# ATSAMA5D225CD1M register map
Vendor: Microchip Technology; Series: SAMA5D2; File version: 0
Registers are 32-bit, read-write, reset 0x0 unless marked. A register's access mark holds for its fields unless they carry their own. Offsets are from the block's base; [hi:lo] are bit positions; {n}, {i} and the like mark numbered series; 'fields as' and 'values as' point back to an identical list.

## PIT — Periodic Interval Timer
Base 0xF8048030; register names take the prefix PIT_
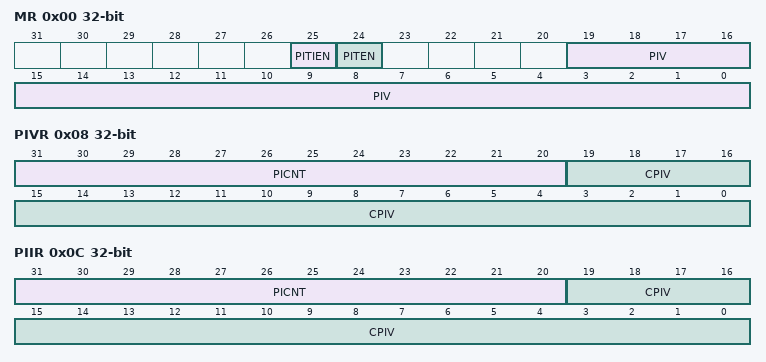
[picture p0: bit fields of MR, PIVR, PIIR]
0x00 MR — Mode Register
  [25] PITIEN — Periodic Interval Timer Interrupt Enable
  [24] PITEN — Period Interval Timer Enabled
  [19:0] PIV — Periodic Interval Value
0x04 SR ro — Status Register
  [0] PITS — Periodic Interval Timer Status
0x08 PIVR ro — Periodic Interval Value Register
  [31:20] PICNT — Periodic Interval Counter
  [19:0] CPIV — Current Periodic Interval Value
0x0C PIIR ro — Periodic Interval Image Register
  fields as PIVR

## PTC — Peripheral Touch Controller
Base 0xFC060000; register names take the prefix PTC_
0x28 CMD 8-bit wo — PTC Command Register
  [3:0] CMD — Host Command
    0=NO_ACTION; 1=STOP (Waits for ongoing execution to complete, then stops.); 2=REST (Stops and resets); 4=ABORT (Stops without waiting for ongoing execution to complete.); 5=RUN (Starts execution (from stopped state))
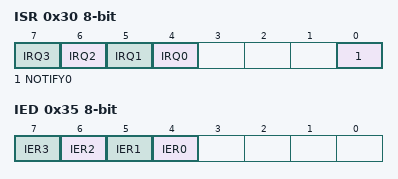
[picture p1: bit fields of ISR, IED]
0x30 ISR 8-bit — PTC Interrupt Status Register
  [n+4] IRQ{n} (n=0..3)
  [0] NOTIFY0 — Notification to the Firmware
0x35 IED 8-bit wo — PTC Enable Register
  [n+4] IER{n} (n=0..3)

## RSTC — Reset Controller
Base 0xF8048000; register names take the prefix RSTC_
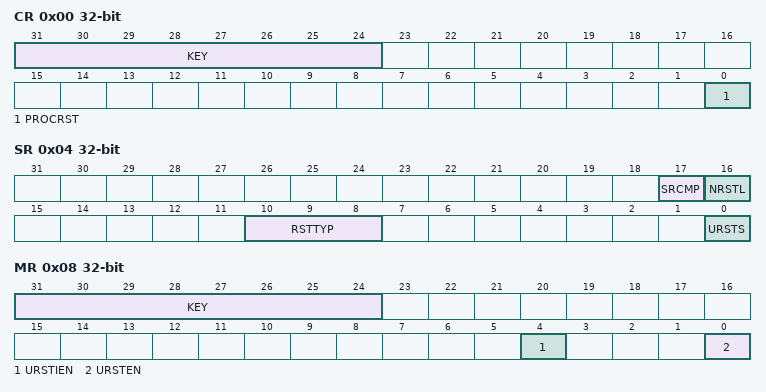
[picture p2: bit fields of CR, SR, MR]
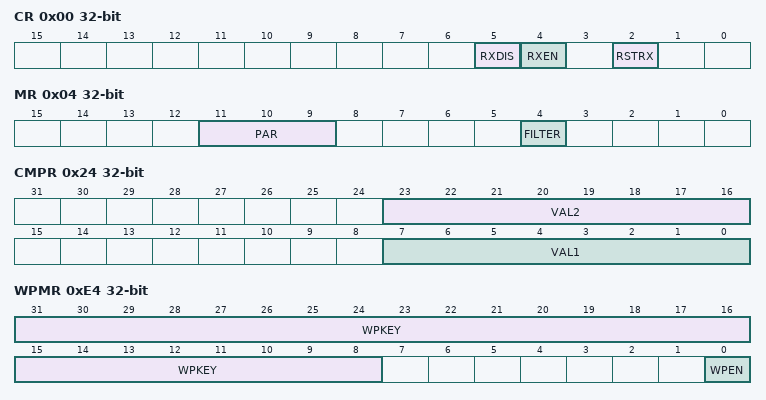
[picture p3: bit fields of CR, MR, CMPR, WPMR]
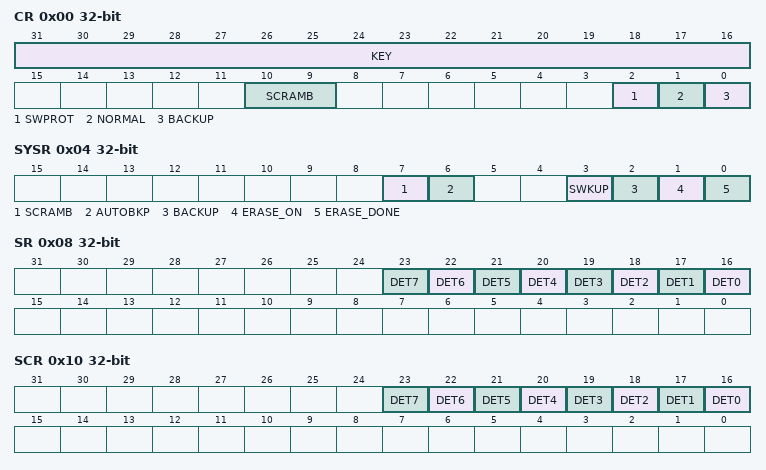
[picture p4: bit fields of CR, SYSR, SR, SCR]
0x00 CR wo — Control Register
  [31:24] KEY — Write Access Password
    165=PASSWD (Writing any other value in this field aborts the write operation.Always reads as 0.)
  [0] PROCRST — Processor Reset
0x04 SR ro — Status Register
  [17] SRCMP — Software Reset Command in Progress
  [16] NRSTL — NRST Pin Level
  [10:8] RSTTYP — Reset Type
    0=GENERAL_RST (Both VDDCORE and VDDBU rising); 1=WKUP_RST (VDDCORE rising); 2=WDT_RST (Watchdog fault occurred); 3=SOFT_RST (Processor reset required by the software); 4=USER_RST (NRST pin detected low)
  [0] URSTS — User Reset Status
0x08 MR — Mode Register
  [31:24] KEY — Write Access Password
    values as CR.KEY
  [4] URSTIEN — User Reset Interrupt Enable
  [0] URSTEN — User Reset Enable

## RXLP — Low Power Asynchronous Receiver
Base 0xF8049000; register names take the prefix RXLP_
0x00 CR wo — Control Register
  [5] RXDIS — Receiver Disable
  [4] RXEN — Receiver Enable
  [2] RSTRX — Reset Receiver
0x04 MR — Mode Register
  [11:9] PAR — Parity Type
    0=EVEN (Even Parity); 1=ODD (Odd Parity); 2=SPACE (Parity forced to 0); 3=MARK (Parity forced to 1); 4=NO (No parity)
  [4] FILTER — Receiver Digital Filter
    0=DISABLED (RXLP does not filter the receive line.); 1=ENABLED (RXLP filters the receive line using a three-sample filter (16x-bit clock) (2 over 3 majority).)
0x18 RHR ro — Receive Holding Register
  [7:0] RXCHR — Received Character
0x20 BRGR — Baud Rate Generator Register
  [1:0] CD — Clock Divisor
0x24 CMPR — Comparison Register
  [23:16] VAL2 — Second Comparison Value for Received Character
  [7:0] VAL1 — First Comparison Value for Received Character
0xE4 WPMR — Write Protection Mode Register
  [31:8] WPKEY — Write Protection Key
    0x52584C=PASSWD (Writing any other value in this field aborts the write operation.Always reads as 0.)
  [0] WPEN — Write Protection Enable

## SCKC — Slow Clock Controller
Base 0xF8048050; register names take the prefix SCKC_
0x00 CR — Slow Clock Controller Configuration Register
  [3] OSCSEL — Slow Clock Selector
    0=RC (Slow clock is the embedded 64 kHz (typical) RC oscillator.); 1=XTAL (Slow clock is the 32.768 kHz crystal oscillator.)

## SECUMOD — Security Module
Base 0xFC040000; register names take the prefix SECUMOD_
0x00 CR wo — Control Register
  [31:16] KEY — Password
  [10:9] SCRAMB — Memory Scrambling Enable
  [2] SWPROT — Software Protection
  [1] NORMAL — Normal Mode
  [0] BACKUP — Backup Mode
0x04 SYSR — System Status Register
  [7] SCRAMB — Scrambling Enabled (RO)
  [6] AUTOBKP — Automatic Backup Mode Enabled (RO)
  [3] SWKUP — SWKUP State (RO)
  [2] BACKUP — Backup Mode (RO)
  [1] ERASE_ON — Erase Process Ongoing (RO)
  [0] ERASE_DONE — Erasable Memories State (RW)
0x08 SR ro — Status Register
  [n+16] DET{n} (n=0..7) — PIOBU Intrusion Detector
0x10 SCR wo — Status Clear Register
  [n+16] DET{n} (n=0..7) — PIOBU Intrusion Detector
0x14 RAMRDY ro — RAM Access Ready Register
  [0] READY — Ready for system access flag
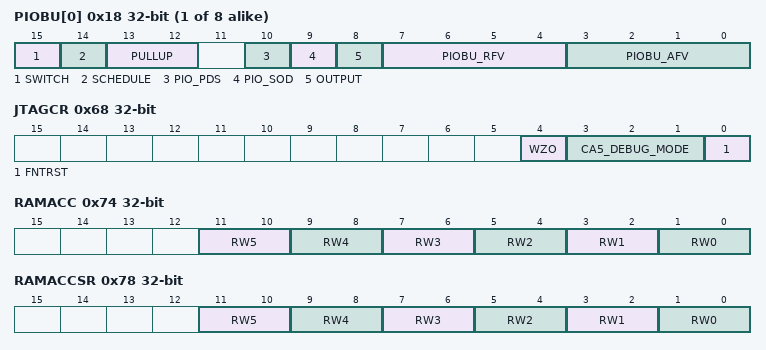
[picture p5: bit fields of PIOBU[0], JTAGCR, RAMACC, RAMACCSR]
{0x18+4i} PIOBU[{i}] (i=0..7) — PIO Backup Register
  [15] SWITCH — Switch State for Intrusion Detection
  [14] SCHEDULE — Pull-up/Down Scheduled
  [13:12] PULLUP — Programmable Pull-up State
  [10] PIO_PDS — Level on the Pin in Input Mode (OUTPUT = 0) (Read-only)
  [9] PIO_SOD — Set/Clear the I/O Line when configured in Output Mode (OUTPUT =1)
  [8] OUTPUT — Configure I/O Line in Input/Output
  [7:4] PIOBU_RFV — PIOBUx Reset Filter Value
  [3:0] PIOBU_AFV — PIOBU Alarm Filter Value
0x68 JTAGCR — JTAG Protection Control Register
  [4] WZO — Write ZERO
  [3:1] CA5_DEBUG_MODE — Cortex-A5 Invasive/Non-Invasive Secure/Non-Secure Debug Permissions
  [0] FNTRST — Force NTRST
0x70 SCRKEY — Scrambling Key Register
  [31:0] SCRKEY — Scrambling Key Value
0x74 RAMACC — RAM Access Rights Register
  [11:10] RW5 — Access right for RAM region [5 Kbytes; 6 Kbytes] (register bank BUREG256b)
  [9:8] RW4 — Access right for RAM region [4 Kbytes; 5 Kbytes]
  [7:6] RW3 — Access right for RAM region [3 Kbytes; 4 Kbytes]
  [5:4] RW2 — Access right for RAM region [2 Kbytes; 3 Kbytes]
  [3:2] RW1 — Access right for RAM region [1 Kbyte; 2 Kbytes]
  [1:0] RW0 — Access right for RAM region [0; 1 Kbyte]
0x78 RAMACCSR — RAM Access Rights Status Register
  [11:10] RW5 — Access right status for RAM region [5 Kbytes; 6 Kbytes] (register bank BUREG256b)
  [9:8] RW4 — Access right status for RAM region [4 Kbytes; 5 Kbytes]
  [7:6] RW3 — Access right status for RAM region [3 Kbytes; 4 Kbytes]
  [5:4] RW2 — Access right status for RAM region [2 Kbytes; 3 Kbytes]
  [3:2] RW1 — Access right status for RAM region [1 Kbytes; 2 Kbytes]
  [1:0] RW0 — Access right status for RAM region [0; 1 Kbyte]
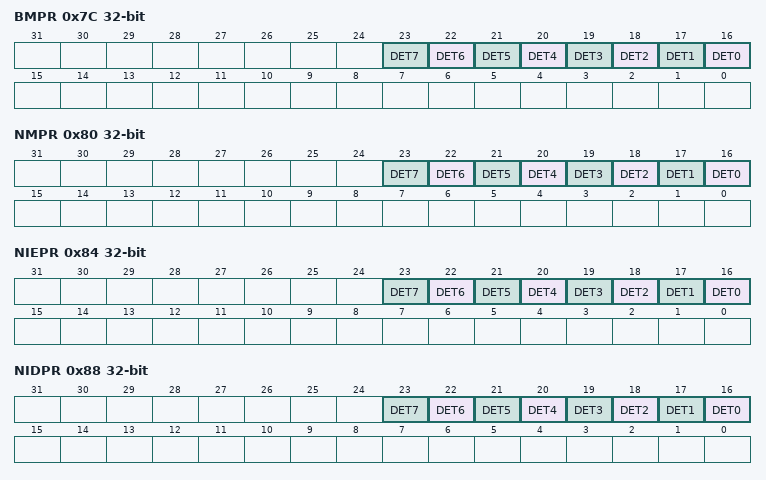
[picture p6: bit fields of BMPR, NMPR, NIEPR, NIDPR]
0x7C BMPR — Backup Mode Protection Register
  [n+16] DET{n} (n=0..7) — PIOBU Intrusion Detector Protection
0x80 NMPR — Normal Mode Protection Register
  [n+16] DET{n} (n=0..7) — PIOBU Intrusion Detector Protection
0x84 NIEPR wo — Normal Interrupt Enable Protection Register
  [n+16] DET{n} (n=0..7) — PIOBU Intrusion Detector Protection Interrupt Enable
0x88 NIDPR wo — Normal Interrupt Disable Protection Register
  [n+16] DET{n} (n=0..7) — PIOBU Intrusion Detector Protection Interrupt Disable
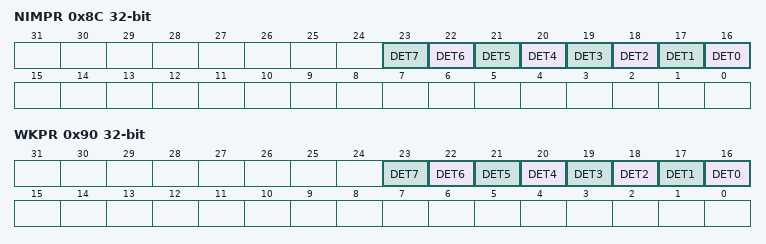
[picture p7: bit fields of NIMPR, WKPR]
0x8C NIMPR ro — Normal Interrupt Mask Protection Register
  [n+16] DET{n} (n=0..7) — PIOBU Intrusion Detector Protection Interrupt Mask
0x90 WKPR — Wakeup Protection Register
  [n+16] DET{n} (n=0..7) — PIOBU Intrusion Detector Protection

## Notices in the file
Copyright (c) 2022 Microchip Technology Inc.
SPDX-License-Identifier: Apache-2.0
Licensed under the Apache License, Version 2.0 (the "License");
you may not use this file except in compliance with the License.
You may obtain a copy of the License at
http://www.apache.org/licenses/LICENSE-2.0
Unless required by applicable law or agreed to in writing, software
distributed under the License is distributed on an "AS IS" BASIS,
WITHOUT WARRANTIES OR CONDITIONS OF ANY KIND, either express or implied.
See the License for the specific language governing permissions and
limitations under the License.
